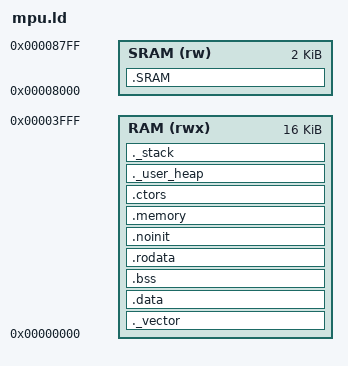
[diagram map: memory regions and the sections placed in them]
/*
 * Copyright 2022 Murray Aickin
 *
 * Permission is hereby granted, free of charge, to any person obtaining a copy
 * of this software and associated documentation files (the "Software"), to deal
 * in the Software without restriction, including without limitation the rights
 * to use, copy, modify, merge, publish, distribute, sublicense, and/or sell
 * copies of the Software, and to permit persons to whom the Software is
 * furnished to do so, subject to the following conditions:
 *
 * The above copyright notice and this permission notice shall be included in all
 * copies or substantial portions of the Software.
 *
 * THE SOFTWARE IS PROVIDED "AS IS", WITHOUT WARRANTY OF ANY KIND, EXPRESS OR
 * IMPLIED, INCLUDING BUT NOT LIMITED TO THE WARRANTIES OF MERCHANTABILITY,
 * FITNESS FOR A PARTICULAR PURPOSE AND NONINFRINGEMENT. IN NO EVENT SHALL THE
 * AUTHORS OR COPYRIGHT HOLDERS BE LIABLE FOR ANY CLAIM, DAMAGES OR OTHER
 * LIABILITY, WHETHER IN AN ACTION OF CONTRACT, TORT OR OTHERWISE, ARISING FROM,
 * OUT OF OR IN CONNECTION WITH THE SOFTWARE OR THE USE OR OTHER DEALINGS IN THE
 * SOFTWARE.
 *
 */

OUTPUT_FORMAT("elf32-littleriscv", "elf32-littleriscv", "elf32-littleriscv")
OUTPUT_ARCH(riscv)
ENTRY(crtStart)

MEMORY {
  RAM (rwx) : ORIGIN = 0x00000000, LENGTH = 0x00004000
  SRAM (rw) : ORIGIN  = 0x00008000, LENGTH = 0x00000800
}

_stack_size = DEFINED(_stack_size) ? _stack_size : 1024;
_heap_size = DEFINED(_heap_size) ? _heap_size : 0;

SECTIONS {

  ._vector ORIGIN(RAM): {
    *startup.o(.start_jump);
    *startup.o(.text);
  } > RAM



  .data :
  {
    *(.rdata)
    *(.rodata .rodata.*)
    *(.gnu.linkonce.r.*)
    *(.data .data.*)
    *(.gnu.linkonce.d.*)
    . = ALIGN(8);
    PROVIDE( __global_pointer$ = . + 0x800 );
    *(.sdata .sdata.*)
    *(.gnu.linkonce.s.*)
    . = ALIGN(8);
    *(.srodata.cst16)
    *(.srodata.cst8)
    *(.srodata.cst4)
    *(.srodata.cst2)
    *(.srodata .srodata.*)
  } > RAM

  .bss (NOLOAD) : {
		. = ALIGN(4);
		/* This is used by the startup in order to initialize the .bss secion */
		_bss_start = .;
    *(.sbss*)
    *(.gnu.linkonce.sb.*)
    *(.bss .bss.*)
    *(.gnu.linkonce.b.*)
    *(COMMON)
		. = ALIGN(4);
		_bss_end = .;
  } > RAM


  .rodata         :
  {
    *(.rdata)
    *(.rodata .rodata.*)
    *(.gnu.linkonce.r.*)
  } > RAM

  .noinit (NOLOAD) : {
      . = ALIGN(4);
      *(.noinit .noinit.*)
      . = ALIGN(4);
  } > RAM

  .memory : {
    *(.text);
    end = .;
  } > RAM

  .ctors          :
  {
    . = ALIGN(4);
    _ctors_start = .;
    KEEP(*(.init_array*))
    KEEP (*(SORT(.ctors.*)))
    KEEP (*(.ctors))
    . = ALIGN(4);
    _ctors_end = .;
    PROVIDE ( END_OF_SW_IMAGE = . );
  } > RAM

  ._user_heap (NOLOAD):
  {
    . = ALIGN(8);
    PROVIDE ( end = . );
    PROVIDE ( _end = . );
    PROVIDE ( _heap_start = .);
    . = . + _heap_size;
    . = ALIGN(8);
    PROVIDE ( _heap_end = .);
  } > RAM

._stack (NOLOAD):
  {
    . = ALIGN(16);
    PROVIDE (_stack_end = .);
    . = . + _stack_size;
    . = ALIGN(16);
    PROVIDE (_stack_start = .);
  } > RAM

  .SRAM : {
   __ram_start = .;
   *(SRAM*)
   __ram_end = .;
   } > SRAM
}
